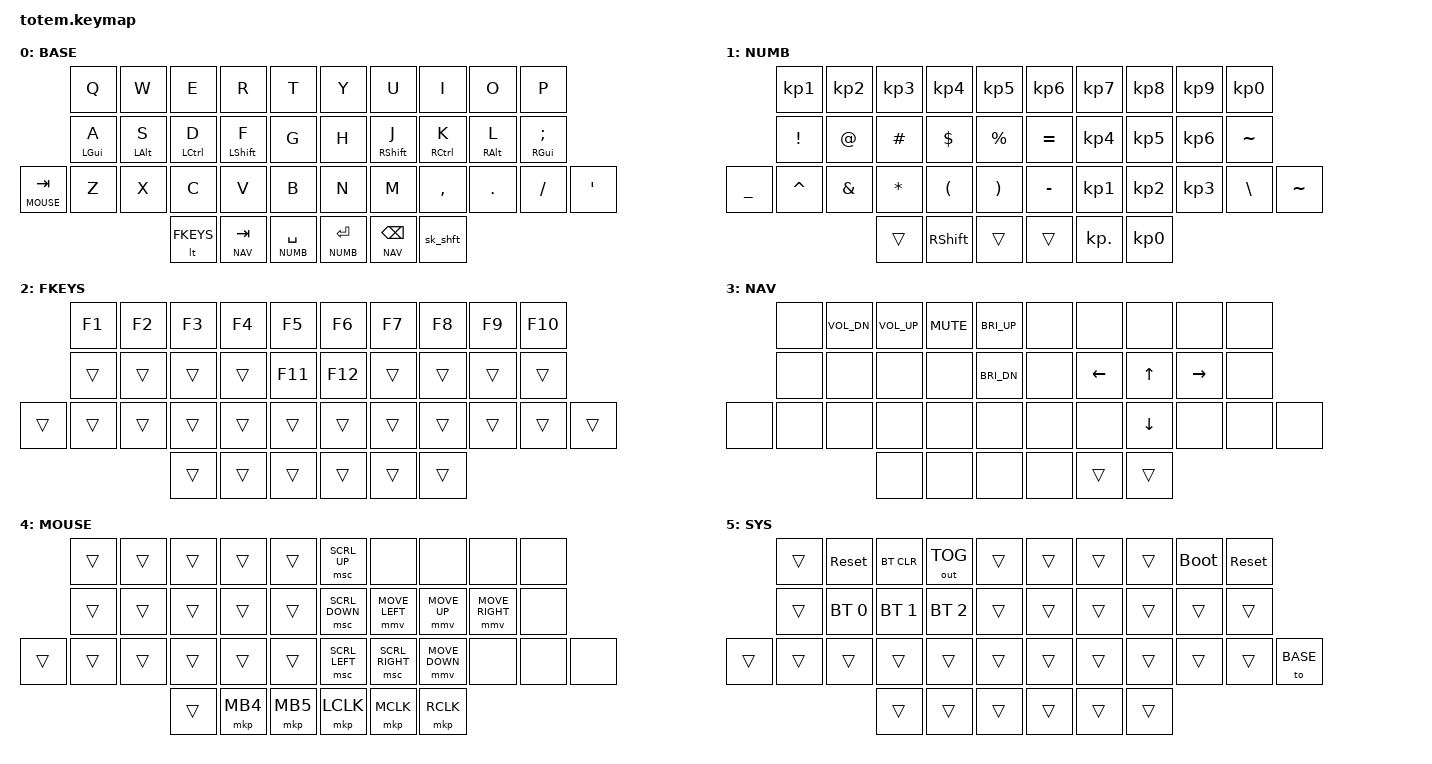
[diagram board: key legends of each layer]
#include "./helper_keypos_38keys.h"
#include <behaviors.dtsi>
#include <dt-bindings/zmk/bt.h>
#include <dt-bindings/zmk/keys.h>
#include <dt-bindings/zmk/outputs.h>
#include <dt-bindings/zmk/pointing.h>


// ▄▄▄▄▄▄▄▄▄▄▄▄▄▄▄▄▄▄▄▄▄▄▄▄▄▄▄▄▄▄▄▄▄▄▄▄▄▄▄▄▄▄▄▄▄▄▄▄▄▄▄▄▄▄▄▄▄▄▄▄▄▄▄▄▄▄▄▄▄▄▄▄▄▄▄▄▄▄▄▄▄▄▄▄▄▄▄▄▄▄▄▄▄▄▄▄▄▄▄▄▄▄▄▄▄▄▄▄▄▄▄▄▄▄▄▄▄▄▄▄▄▄▄▄▄▄▄▄▄▄▄▄▄▄▄▄▄▄▄▄▄▄▄▄▄▄▄▄▄
#define BASE	0
#define NUMB 	1
#define NAV		2
#define FKEYS	3
#define MOUSE	4
#define SYS		5

#define KEYS_L LT0 LT1 LT2 LT3 LT4 LM0 LM1 LM2 LM3 LM4 LB0 LB1 LB2 LB3 LB4 LB5  // left-hand keys
#define KEYS_R RT0 RT1 RT2 RT3 RT4 RM0 RM1 RM2 RM3 RM4 RB0 RB1 RB2 RB3 RB4 RB5 // right-hand keys
#define THUMBS LH2 LH1 LH0 RH0 RH1 RH2


// ▄▄▄▄▄▄▄▄▄▄▄▄▄▄▄▄▄▄▄▄▄▄▄▄▄▄▄▄▄▄▄▄▄▄▄▄▄▄▄▄▄▄▄▄▄▄▄▄▄▄▄▄▄▄▄▄▄▄▄▄▄▄▄▄▄▄▄▄▄▄▄▄▄▄▄▄▄▄▄▄▄▄▄▄▄▄▄▄▄▄▄▄▄▄▄▄▄▄▄▄▄▄▄▄▄▄▄▄▄▄▄▄▄▄▄▄▄▄▄▄▄▄▄▄▄▄▄▄▄▄▄▄▄▄▄▄▄▄▄▄▄▄▄▄▄▄▄▄▄
	&lt {
    tapping-term-ms = <150>;
	};

	&sk {
		quick-release;
	};
	
// ▄▄▄▄▄▄▄▄▄▄▄▄▄▄▄▄▄▄▄▄▄▄▄▄▄▄▄▄▄▄▄▄▄▄▄▄▄▄▄▄▄▄▄▄▄▄▄▄▄▄▄▄▄▄▄▄▄▄▄▄▄▄▄▄▄▄▄▄▄▄▄▄▄▄▄▄▄▄▄▄▄▄▄▄▄▄▄▄▄▄▄▄▄▄▄▄▄▄▄▄▄▄▄▄▄▄▄▄▄▄▄▄▄▄▄▄▄▄▄▄▄▄▄▄▄▄▄▄▄▄▄▄▄▄▄▄▄▄▄▄▄▄▄▄▄▄▄▄▄
/ {
    behaviors {
        hml: home_row_mods_left {
            compatible = "zmk,behavior-hold-tap";
            #binding-cells = <2>;
            flavor = "balanced";
            tapping-term-ms = <280>;
            quick-tap-ms = <210>;                				// repeat on tap-into-hold
            require-prior-idle-ms = <150>;
            bindings = <&kp>, <&kp>;

            hold-trigger-key-positions = <KEYS_R THUMBS>;
            hold-trigger-on-release;             				// delay positional check until key-release
        };

        hmr: home_row_mods_right {
            compatible = "zmk,behavior-hold-tap";
            #binding-cells = <2>;
            flavor = "balanced";
            tapping-term-ms = <280>;
            quick-tap-ms = <210>;                				// repeat on tap-into-hold
            require-prior-idle-ms = <150>;
            bindings = <&kp>, <&kp>;

            hold-trigger-key-positions = <KEYS_L THUMBS>;
            hold-trigger-on-release;
        };

        sk_shft: sticky_shift_caps_word {
            compatible = "zmk,behavior-mod-morph";
            #binding-cells = <0>;
            bindings = <&sk RSHIFT>, <&caps_word>;

            mods = <(MOD_LSFT | MOD_RSFT)>;
        };
    };
	
// ▄▄▄▄▄▄▄▄▄▄▄▄▄▄▄▄▄▄▄▄▄▄▄▄▄▄▄▄▄▄▄▄▄▄▄▄▄▄▄▄▄▄▄▄▄▄▄▄▄▄▄▄▄▄▄▄▄▄▄▄▄▄▄▄▄▄▄▄▄▄▄▄▄▄▄▄▄▄▄▄▄▄▄▄▄▄▄▄▄▄▄▄▄▄▄▄▄▄▄▄▄▄▄▄▄▄▄▄▄▄▄▄▄▄▄▄▄▄▄▄▄▄▄▄▄▄▄▄▄▄▄▄▄▄▄▄▄▄▄▄▄▄▄▄▄▄▄▄▄	
    combos {
        compatible = "zmk,combos";

        combo_esc {
            timeout-ms = <50>;
            key-positions = <LT3 LT2>;
            bindings = <&kp ESC>;
        };

        combo_bksp {
            timeout-ms = <50>;
            key-positions = <RT3 RT2>;
            bindings = <&kp BSPC>;
        };
		
		combo_del {
            timeout-ms = <50>;
            key-positions = <RB4 RB5>;
            bindings = <&kp DEL>;
        };
		
		combo_tab {
            timeout-ms = <50>;
            key-positions = <LB5 LB4>;
            bindings = <&kp TAB>;
        };
		
		
    };
	
// ▄▄▄▄▄▄▄▄▄▄▄▄▄▄▄▄▄▄▄▄▄▄▄▄▄▄▄▄▄▄▄▄▄▄▄▄▄▄▄▄▄▄▄▄▄▄▄▄▄▄▄▄▄▄▄▄▄▄▄▄▄▄▄▄▄▄▄▄▄▄▄▄▄▄▄▄▄▄▄▄▄▄▄▄▄▄▄▄▄▄▄▄▄▄▄▄▄▄▄▄▄▄▄▄▄▄▄▄▄▄▄▄▄▄▄▄▄▄▄▄▄▄▄▄▄▄▄▄▄▄▄▄▄▄▄▄▄▄▄▄▄▄▄▄▄▄▄▄▄	
    conditional_layers {
        compatible = "zmk,conditional-layers";

        sys_layer {
            if-layers = <NUMB NAV>;
            then-layer = <SYS>;
        };
		
    };
	
// ▄▄▄▄▄▄▄▄▄▄▄▄▄▄▄▄▄▄▄▄▄▄▄▄▄▄▄▄▄▄▄▄▄▄▄▄▄▄▄▄▄▄▄▄▄▄▄▄▄▄▄▄▄▄▄▄▄▄▄▄▄▄▄▄▄▄▄▄▄▄▄▄▄▄▄▄▄▄▄▄▄▄▄▄▄▄▄▄▄▄▄▄▄▄▄▄▄▄▄▄▄▄▄▄▄▄▄▄▄▄▄▄▄▄▄▄▄▄▄▄▄▄▄▄▄▄▄▄▄▄▄▄▄▄▄▄▄▄▄▄▄▄▄▄▄▄▄▄▄
    keymap {
        compatible = "zmk,keymap";

        base_layer {
            label = "BASE";
            bindings = <
				&kp Q 			&kp W   		&kp E           &kp R          	&kp T				&kp Y         	&kp U        	&kp I         	&kp O    	  	&kp P
			    &hml LGUI A		&hml LALT S  	&hml LCTRL D	&hml LSHFT F   	&kp G    			&kp H         	&hmr RSHFT J 	&hmr RCTRL K  	&hmr RALT L  	&hmr RGUI SEMI
&lt MOUSE TAB	&kp Z			&kp X  			&kp C			&kp V          	&kp B    			&kp N         	&kp M			&kp COMMA		&kp DOT			&kp FSLH  		&kp SQT
												&lt FKEYS		&lt NAV TAB		&lt NUMB SPACE      &lt NUMB RET	&lt NAV BSPC	&sk_shft
				>;
        };

        numb_layer {
            label = "NUMB";
            bindings = <
				&kp KP_N1		&kp KP_N2		&kp KP_N3  		&kp KP_N4   	&kp KP_N5    		&kp KP_N6  	  	&kp KP_N7  		&kp KP_N8  		&kp KP_N9   	&kp KP_N0
				&kp EXCL  		&kp AT			&kp POUND		&kp DLLR		&kp PRCNT    		&kp EQUAL  		&kp KP_N4  		&kp KP_N5 		&kp KP_N6  		&kp TILDE
	&kp UNDER  	&kp CARET   	&kp AMPS   		&kp STAR    	&kp LPAR     	&kp RPAR    		&kp MINUS  		&kp KP_N1 		&kp KP_N2  		&kp KP_N3   	&kp BSLH   		&kp TILDE
												&trans    		&kp RSHFT  	 	&trans     			&trans     		&kp KP_DOT   	&kp KP_N0
            >;
        };

        fkeys_layer {
            label = "FKEYS";
            bindings = <
				&kp F1			&kp F2			&kp F3  		&kp F4   		&kp F5    				&kp F6  	  	&kp F7  		&kp F8  		&kp F9		&kp F10
				&trans  		&trans			&trans			&trans			&kp F11    				&kp F12  		&trans  		&trans 			&trans  	&trans
	&trans  	&trans   		&trans   		&trans   		&trans     		&trans    				&trans  		&trans 			&trans  		&trans  	&trans   		&trans
												&trans    		&trans  	 	&trans     				&trans     		&trans   		&trans
            >;
        };		

        nav_layer {
            label = "NAV";
            bindings = <
				&none  		&kp C_VOL_DN  	&kp C_VOL_UP	&kp C_MUTE		&kp C_BRI_UP    			&none     	&none	 	&none		&none    	&none
				&none  		&none  			&none  			&none  			&kp C_BRI_DN    			&none		&kp LEFT	&kp UP		&kp RIGHT   &none
		&none 	&none  		&none	  		&none	  		&none	  		&none           			&none     	&none		&kp DOWN	&none       &none  	&none
											&none   		&none	  		&none           			&none     	&trans		&trans
            >;
        };
		
		mouse_layer {
            label = "MOUSE";
            bindings = <
				&trans   	&trans   	&trans  	&trans		&trans    					&msc SCRL_UP  		&none  			&none  				&none  				&none
				&trans		&trans		&trans		&trans		&trans						&msc SCRL_DOWN  	&mmv MOVE_LEFT 	&mmv MOVE_UP  		&mmv MOVE_RIGHT	 	&none
	&trans  	&trans		&trans		&trans		&trans      &trans    					&msc SCRL_LEFT		&msc SCRL_RIGHT	&mmv MOVE_DOWN	 	&none 				&none  		&none
										&trans		&mkp MB4    &mkp MB5   					&mkp LCLK   		&mkp MCLK  		&mkp RCLK
            >;
        };
		
		system_layer {
            label = "SYS";
            bindings = <
				&trans		&sys_reset		&bt BT_CLR		&out OUT_TOG  &trans					&trans		&trans		&trans  	&bootloader		&sys_reset
				&trans  	&bt BT_SEL 0	&bt BT_SEL 1	&bt BT_SEL 2  &trans					&trans		&trans		&trans		&trans			&trans
	&trans  	&trans		&trans			&trans			&trans        &trans    				&trans		&trans		&trans		&trans			&trans		&to BASE
										    &trans        	&trans        &trans    				&trans		&trans		&trans
            >;
        };		




    };
	
	
};
